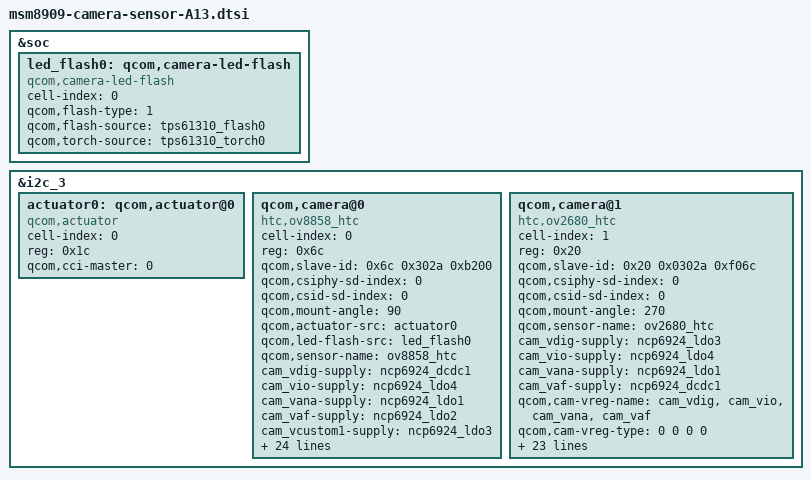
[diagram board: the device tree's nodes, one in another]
/*
 * Copyright (c) 2014, The Linux Foundation. All rights reserved.
 *
 * This program is free software; you can redistribute it and/or modify
 * it under the terms of the GNU General Public License version 2 and
 * only version 2 as published by the Free Software Foundation.
 *
 * This program is distributed in the hope that it will be useful,
 * but WITHOUT ANY WARRANTY; without even the implied warranty of
 * MERCHANTABILITY or FITNESS FOR A PARTICULAR PURPOSE.  See the
 * GNU General Public License for more details.
 */

&soc {
	led_flash0: qcom,camera-led-flash {
		cell-index = <0>;
		compatible = "qcom,camera-led-flash";
		qcom,flash-type = <1>;
		qcom,flash-source = <&tps61310_flash0>;
		qcom,torch-source = <&tps61310_torch0>;
	};
};

&i2c_3 {
	actuator0: qcom,actuator@0 {
		cell-index = <0>;
		reg = <0x1c>;
		compatible = "qcom,actuator";
		qcom,cci-master = <0>;
	};

	qcom,camera@0 {
		cell-index = <0>;
		compatible = "htc,ov8858_htc";
		reg = <0x6c>;
		qcom,slave-id = <0x6c 0x302a 0xb200>;
		qcom,csiphy-sd-index = <0>;
		qcom,csid-sd-index = <0>;
		qcom,mount-angle = <90>;
		qcom,actuator-src = <&actuator0>;
		qcom,led-flash-src = <&led_flash0>;
		qcom,sensor-name = "ov8858_htc";
		cam_vdig-supply = <&ncp6924_dcdc1>;//V_CAM_D1V2
		cam_vio-supply = <&ncp6924_ldo4>;
		cam_vana-supply = <&ncp6924_ldo1>;
		cam_vaf-supply = <&ncp6924_ldo2>;
		cam_vcustom1-supply = <&ncp6924_ldo3>;//V_CAM2_D1V2
		qcom,cam-vreg-name = "cam_vdig", "cam_vio", "cam_vana", "cam_vaf", "cam_vcustom1";
		qcom,cam-vreg-type = <0 0 0 0 0>;
		qcom,cam-vreg-min-voltage = <1200000 1800000 2800000 2800000 1600000>;
		qcom,cam-vreg-max-voltage = <1200000 1800000 2800000 2800000 1600000>;
		qcom,cam-vreg-op-mode = <0 0 0 0 0>;
		qcom,cam-vreg-gpios-index = <99 99 99 99 99>;
		pinctrl-names = "cam_default", "cam_suspend";
		pinctrl-0 = <&cam_sensor_mclk0_default &cam_sensor_rear_default>;
		pinctrl-1 = <&cam_sensor_mclk0_sleep &cam_sensor_rear_sleep>;
		gpios = <&msm_gpio 26 0>,
			<&msm_gpio 35 0>;

		qcom,gpio-reset = <1>;
		qcom,gpio-req-tbl-num = <0 1>;
		qcom,gpio-req-tbl-flags = <1 0>;
		qcom,gpio-req-tbl-label = "CAMIF_MCLK",
			"CAM_RST";

		qcom,csi-lane-assign = <0x4320>;
		qcom,csi-lane-mask = <0x7>;
		qcom,sensor-position = <0>;
		qcom,cci-master = <0>;
		status = "ok";
		clocks = <&clock_gcc clk_mclk0_clk_src>,
				<&clock_gcc clk_gcc_camss_mclk0_clk>;
		clock-names = "cam_src_clk", "cam_clk";
	};

	qcom,camera@1 {
		cell-index = <1>;
		compatible = "htc,ov2680_htc";
		reg = <0x20>;
		qcom,slave-id = <0x20 0x0302a 0xf06c>;
		qcom,csiphy-sd-index = <0>;
		qcom,csid-sd-index = <0>;
		qcom,mount-angle = <270>;
		qcom,sensor-name = "ov2680_htc";
		cam_vdig-supply = <&ncp6924_ldo3>;//V_CAM2_D1V2
		cam_vio-supply = <&ncp6924_ldo4>;
		cam_vana-supply = <&ncp6924_ldo1>;
		cam_vaf-supply = <&ncp6924_dcdc1>;//V_CAM_D1V2
		qcom,cam-vreg-name = "cam_vdig", "cam_vio", "cam_vana", "cam_vaf";
		qcom,cam-vreg-type = <0 0 0 0>;
		qcom,cam-vreg-min-voltage = <1600000 1800000 2800000 1200000>;
		qcom,cam-vreg-max-voltage = <1600000 1800000 2800000 1200000>;
		qcom,cam-vreg-op-mode = <0 0 0 0>;
		qcom,cam-vreg-gpios-index = <99 99 99 99>;
		pinctrl-names = "cam_default", "cam_suspend";
		pinctrl-0 = <&cam_sensor_mclk1_default &cam_sensor_front_default>;
		pinctrl-1 = <&cam_sensor_mclk1_sleep &cam_sensor_front_sleep>;
		gpios = <&msm_gpio 27 0>,
			<&msm_gpio 28 0>,
			<&msm_gpio 23 0>;
		qcom,gpio-reset = <1>;
		qcom,gpio-custom1 = <2>;
		qcom,gpio-req-tbl-num = <0 1 2>;
		qcom,gpio-req-tbl-flags = <1 0 0>;
		qcom,gpio-req-tbl-label = "CAMIF_MCLK",
			"CAM_RST",
			"FRONT_SID";
		qcom,csi-lane-assign = <0x0004>;
		qcom,csi-lane-mask = <0x18>;
		qcom,sensor-position = <1>;
		qcom,cci-master = <0>;
		status = "ok";
		clocks = <&clock_gcc clk_mclk1_clk_src>,
				<&clock_gcc clk_gcc_camss_mclk1_clk>;
		clock-names = "cam_src_clk", "cam_clk";
	};
};
